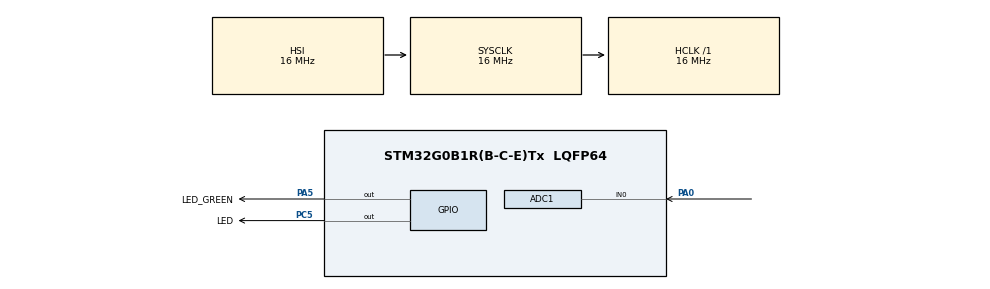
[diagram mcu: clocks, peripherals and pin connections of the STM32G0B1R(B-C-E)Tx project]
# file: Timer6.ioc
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ADC1.Channel-0\#ChannelRegularConversion=ADC_CHANNEL_0
ADC1.NbrOfConversionFlag=1
ADC1.Rank-0\#ChannelRegularConversion=1
ADC1.SamplingTime-0\#ChannelRegularConversion=ADC_SAMPLINGTIME_COMMON_1
ADC1.SelectedChannel=ADC_CHANNEL_0
ADC1.master=1
Mcu.Family=STM32G0
Mcu.Name=STM32G0B1R(B-C-E)Tx
Mcu.Package=LQFP64
NVIC.TIM6_DAC_LPTIM1_IRQn=true\:0\:0\:false\:false\:true\:true\:true\:true
PA0.Mode=IN0
PA0.Signal=ADC1_IN0
PA13.GPIO_Label=TMS
PA13.Mode=Serial_Wire
PA13.Signal=SYS_SWDIO
PA14-BOOT0.GPIO_Label=TCK
PA14-BOOT0.Mode=Serial_Wire
PA14-BOOT0.Signal=SYS_SWCLK
PA3.GPIO_Label=USART2_RX [STLK_RX]
PA3.Signal=USART2_RX
PA5.GPIO_Label=LED_GREEN
PA5.GPIO_Speed=GPIO_SPEED_FREQ_HIGH
PA5.Signal=GPIO_Output
PC13.Mode=SYS_WakeUp1
PC13.Signal=SYS_WKUP2
PC14-OSC32_IN\ (PC14).Mode=LSE-External-Oscillator
PC14-OSC32_IN\ (PC14).Signal=RCC_OSC32_IN
PC15-OSC32_OUT\ (PC15).Mode=LSE-External-Oscillator
PC15-OSC32_OUT\ (PC15).Signal=RCC_OSC32_OUT
PC5.GPIO_Label=LED
PC5.Signal=GPIO_Output
PD5.GPIO_Label=USART2_TX [STLK_TX]
PD5.Signal=USART2_TX
PF0-OSC_IN\ (PF0).GPIO_Label=MCO
PF0-OSC_IN\ (PF0).Mode=HSE-External-Clock-Source
PF0-OSC_IN\ (PF0).Signal=RCC_OSC_IN
ProjectManager.HeapSize=0x200
ProjectManager.StackSize=0x400
ProjectManager.TargetToolchain=STM32CubeIDE
RCC.AHBFreq_Value=16000000
RCC.CortexFreq_Value=16000000
RCC.EXTERNAL_CLOCK_VALUE=12288000
RCC.HCLKFreq_Value=16000000
RCC.HSE_VALUE=8000000
RCC.HSI48_VALUE=48000000
RCC.HSI_VALUE=16000000
RCC.SYSCLKFreq_VALUE=16000000
RCC.USBFreq_Value=48000000
RCC.VCOOutputFreq_Value=128000000
TIM6.Period=2000
TIM6.Prescaler=16000
VP_TIM6_VS_ClockSourceINT.Mode=Enable_Timer
board=NUCLEO-G0B1RE

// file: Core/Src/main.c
/* USER CODE BEGIN Header */
/**
  ******************************************************************************
  * @file           : main.c
  * @brief          : Main program body
  ******************************************************************************
  * @attention
  *
  * Copyright (c) 2024 STMicroelectronics.
  * All rights reserved.
  *
  * This software is licensed under terms that can be found in the LICENSE file
  * in the root directory of this software component.
  * If no LICENSE file comes with this software, it is provided AS-IS.
  *
  ******************************************************************************
  */
/* USER CODE END Header */
#include "main.h"

/* USER CODE BEGIN PD */
#define TIME_2S 0x7D0
#define SIZE_BUFFER 4
#define INIT_VALUE 0
#define TRUE 1
#define FALSE 0
#define TIME 3000
/* USER CODE END PD */

ADC_HandleTypeDef hadc1;

TIM_HandleTypeDef htim6;

/* USER CODE BEGIN PV */

uint8_t BufferTx[SIZE_BUFFER] = "PING";
uint8_t BufferRx[SIZE_BUFFER];

/* USER CODE END PV */

void SystemClock_Config(void);
static void MX_GPIO_Init(void);
static void MX_TIM6_Init(void);
static void MX_ADC1_Init(void);

int main(void)
{
  /* USER CODE BEGIN 1 */

  uint8_t flag = TRUE;
  /* USER CODE END 1 */

  /* MCU Configuration--------------------------------------------------------*/

  /* Reset of all peripherals, Initializes the Flash interface and the Systick. */
  HAL_Init();

  /* Configure the system clock */
  SystemClock_Config();

  /* Initialize all configured peripherals */
  MX_GPIO_Init();
  MX_TIM6_Init();
  MX_ADC1_Init();
  /* USER CODE BEGIN 2 */
  //HAL_UART_Transmit_IT(&huart2, &BufferTx[INIT_VALUE], SIZE_BUFFER);

  /* USER CODE END 2 */

  /* Infinite loop */
  while (1)
  {

  }
}

void SystemClock_Config(void)
{
  RCC_OscInitTypeDef RCC_OscInitStruct = {0};
  RCC_ClkInitTypeDef RCC_ClkInitStruct = {0};

  /** Configure the main internal regulator output voltage
  */
  HAL_PWREx_ControlVoltageScaling(PWR_REGULATOR_VOLTAGE_SCALE1);

  /** Initializes the RCC Oscillators according to the specified parameters
  * in the RCC_OscInitTypeDef structure.
  */
  RCC_OscInitStruct.OscillatorType = RCC_OSCILLATORTYPE_HSI;
  RCC_OscInitStruct.HSIState = RCC_HSI_ON;
  RCC_OscInitStruct.HSIDiv = RCC_HSI_DIV1;
  RCC_OscInitStruct.HSICalibrationValue = RCC_HSICALIBRATION_DEFAULT;
  RCC_OscInitStruct.PLL.PLLState = RCC_PLL_NONE;
  if (HAL_RCC_OscConfig(&RCC_OscInitStruct) != HAL_OK)
  {
    Error_Handler();
  }

  /** Initializes the CPU, AHB and APB buses clocks
  */
  RCC_ClkInitStruct.ClockType = RCC_CLOCKTYPE_HCLK|RCC_CLOCKTYPE_SYSCLK
                              |RCC_CLOCKTYPE_PCLK1;
  RCC_ClkInitStruct.SYSCLKSource = RCC_SYSCLKSOURCE_HSI;
  RCC_ClkInitStruct.AHBCLKDivider = RCC_SYSCLK_DIV1;
  RCC_ClkInitStruct.APB1CLKDivider = RCC_HCLK_DIV1;

  if (HAL_RCC_ClockConfig(&RCC_ClkInitStruct, FLASH_LATENCY_0) != HAL_OK)
  {
    Error_Handler();
  }
}

static void MX_ADC1_Init(void)
{

  ADC_ChannelConfTypeDef sConfig = {0};

  /** Configure the global features of the ADC (Clock, Resolution, Data Alignment and number of conversion)
  */
  hadc1.Instance = ADC1;
  hadc1.Init.ClockPrescaler = ADC_CLOCK_SYNC_PCLK_DIV2;
  hadc1.Init.Resolution = ADC_RESOLUTION_12B;
  hadc1.Init.DataAlign = ADC_DATAALIGN_RIGHT;
  hadc1.Init.ScanConvMode = ADC_SCAN_DISABLE;
  hadc1.Init.EOCSelection = ADC_EOC_SINGLE_CONV;
  hadc1.Init.LowPowerAutoWait = DISABLE;
  hadc1.Init.LowPowerAutoPowerOff = DISABLE;
  hadc1.Init.ContinuousConvMode = DISABLE;
  hadc1.Init.NbrOfConversion = 1;
  hadc1.Init.DiscontinuousConvMode = DISABLE;
  hadc1.Init.ExternalTrigConv = ADC_SOFTWARE_START;
  hadc1.Init.ExternalTrigConvEdge = ADC_EXTERNALTRIGCONVEDGE_NONE;
  hadc1.Init.DMAContinuousRequests = DISABLE;
  hadc1.Init.Overrun = ADC_OVR_DATA_PRESERVED;
  hadc1.Init.SamplingTimeCommon1 = ADC_SAMPLETIME_1CYCLE_5;
  hadc1.Init.SamplingTimeCommon2 = ADC_SAMPLETIME_1CYCLE_5;
  hadc1.Init.OversamplingMode = DISABLE;
  hadc1.Init.TriggerFrequencyMode = ADC_TRIGGER_FREQ_HIGH;
  if (HAL_ADC_Init(&hadc1) != HAL_OK)
  {
    Error_Handler();
  }

  /** Configure Regular Channel
  */
  sConfig.Channel = ADC_CHANNEL_0;
  sConfig.Rank = ADC_REGULAR_RANK_1;
  sConfig.SamplingTime = ADC_SAMPLINGTIME_COMMON_1;
  if (HAL_ADC_ConfigChannel(&hadc1, &sConfig) != HAL_OK)
  {
    Error_Handler();
  }

}

static void MX_TIM6_Init(void)
{

  TIM_MasterConfigTypeDef sMasterConfig = {0};

  /* USER CODE BEGIN TIM6_Init 1 */

  /*
  FTimer = FSource / Preescaler
  For 1 ms the frequency is 1000 hz, calculate
  the preescaler

  1 ms = 1 / 1000 = 0.001 s
  f = 1/t = 1/ 0.001 s = 1000 hz

  Preescaler = FSource/FTimer
  Preescaler = 16 Mhz / 1000 hz
  Preescaler = 64000

  Each count of the period is equal to 1 ms
  For that reason the period is 2000 ms -> 2 s
   */

  /* USER CODE END TIM6_Init 1 */
  htim6.Instance = TIM6;
  htim6.Init.Prescaler = 16000;
  htim6.Init.CounterMode = TIM_COUNTERMODE_UP;
  htim6.Init.Period = 2000;
  htim6.Init.AutoReloadPreload = TIM_AUTORELOAD_PRELOAD_DISABLE;
  if (HAL_TIM_Base_Init(&htim6) != HAL_OK)
  {
    Error_Handler();
  }
  sMasterConfig.MasterOutputTrigger = TIM_TRGO_RESET;
  sMasterConfig.MasterSlaveMode = TIM_MASTERSLAVEMODE_DISABLE;
  if (HAL_TIMEx_MasterConfigSynchronization(&htim6, &sMasterConfig) != HAL_OK)
  {
    Error_Handler();
  }
  /* USER CODE BEGIN TIM6_Init 2 */

  HAL_TIM_Base_Start_IT( &htim6 );
  /* USER CODE END TIM6_Init 2 */

}

static void MX_GPIO_Init(void)
{
  GPIO_InitTypeDef GPIO_InitStruct = {0};

  /* GPIO Ports Clock Enable */
  __HAL_RCC_GPIOC_CLK_ENABLE();
  __HAL_RCC_GPIOF_CLK_ENABLE();
  __HAL_RCC_GPIOA_CLK_ENABLE();
  __HAL_RCC_GPIOD_CLK_ENABLE();

  /*Configure GPIO pin Output Level */
  HAL_GPIO_WritePin(LED_GREEN_GPIO_Port, LED_GREEN_Pin, GPIO_PIN_RESET);

  /*Configure GPIO pin Output Level */
  HAL_GPIO_WritePin(LED_GPIO_Port, LED_Pin, GPIO_PIN_RESET);

  /*Configure GPIO pin : USART2_RX_Pin */
  GPIO_InitStruct.Pin = USART2_RX_Pin;
  GPIO_InitStruct.Mode = GPIO_MODE_AF_PP;
  GPIO_InitStruct.Pull = GPIO_NOPULL;
  GPIO_InitStruct.Speed = GPIO_SPEED_FREQ_LOW;
  GPIO_InitStruct.Alternate = GPIO_AF1_USART2;
  HAL_GPIO_Init(USART2_RX_GPIO_Port, &GPIO_InitStruct);

  /*Configure GPIO pin : LED_GREEN_Pin */
  GPIO_InitStruct.Pin = LED_GREEN_Pin;
  GPIO_InitStruct.Mode = GPIO_MODE_OUTPUT_PP;
  GPIO_InitStruct.Pull = GPIO_NOPULL;
  GPIO_InitStruct.Speed = GPIO_SPEED_FREQ_HIGH;
  HAL_GPIO_Init(LED_GREEN_GPIO_Port, &GPIO_InitStruct);

  /*Configure GPIO pin : LED_Pin */
  GPIO_InitStruct.Pin = LED_Pin;
  GPIO_InitStruct.Mode = GPIO_MODE_OUTPUT_PP;
  GPIO_InitStruct.Pull = GPIO_NOPULL;
  GPIO_InitStruct.Speed = GPIO_SPEED_FREQ_LOW;
  HAL_GPIO_Init(LED_GPIO_Port, &GPIO_InitStruct);

  /*Configure GPIO pin : USART2_TX_Pin */
  GPIO_InitStruct.Pin = USART2_TX_Pin;
  GPIO_InitStruct.Mode = GPIO_MODE_AF_PP;
  GPIO_InitStruct.Pull = GPIO_NOPULL;
  GPIO_InitStruct.Speed = GPIO_SPEED_FREQ_LOW;
  GPIO_InitStruct.Alternate = GPIO_AF0_USART2;
  HAL_GPIO_Init(USART2_TX_GPIO_Port, &GPIO_InitStruct);

}

/* USER CODE BEGIN 4 */

/*Function of timer interruption*/
void HAL_TIM_PeriodElapsedCallback(TIM_HandleTypeDef *htim){

	__HAL_TIM_SET_AUTORELOAD(&htim6,TIME_2S);
    HAL_GPIO_TogglePin( LED_GPIO_Port, LED_Pin );
}

/* USER CODE END 4 */

void Error_Handler(void)
{
  __disable_irq();
  while (1)
  {
  }
}
